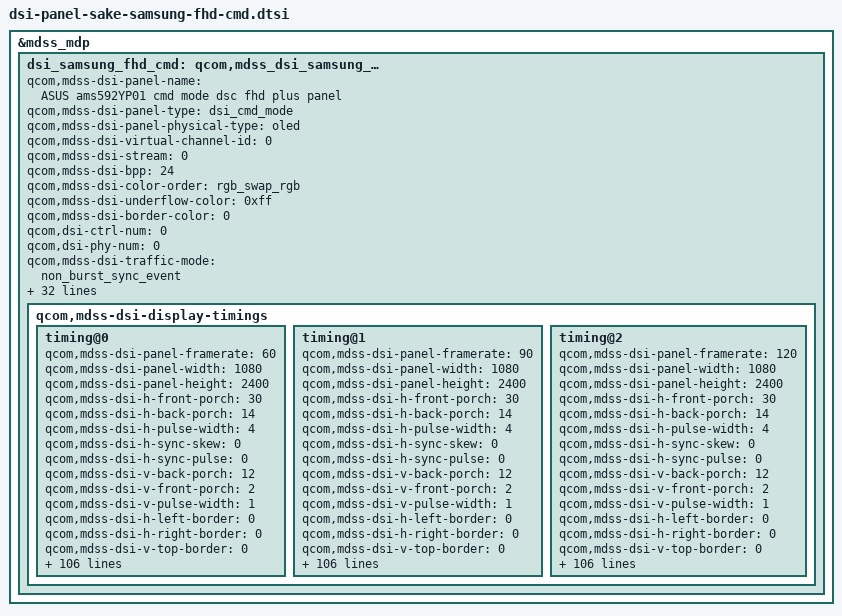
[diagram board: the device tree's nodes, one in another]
&mdss_mdp {
	dsi_samsung_fhd_cmd: qcom,mdss_dsi_samsung_fhd_cmd {
		qcom,mdss-dsi-panel-name = "ASUS ams592YP01 cmd mode dsc fhd plus panel";
		qcom,mdss-dsi-panel-type = "dsi_cmd_mode";
		qcom,mdss-dsi-panel-physical-type = "oled";
		qcom,mdss-dsi-virtual-channel-id = <0>;
		qcom,mdss-dsi-stream = <0>;
		qcom,mdss-dsi-bpp = <24>;
		qcom,mdss-dsi-color-order = "rgb_swap_rgb";
		qcom,mdss-dsi-underflow-color = <0xff>;
		qcom,mdss-dsi-border-color = <0>;

		qcom,dsi-ctrl-num = <0>;
		qcom,dsi-phy-num = <0>;

		qcom,mdss-dsi-traffic-mode = "non_burst_sync_event";
		qcom,mdss-dsi-lane-map = "lane_map_0123";
		qcom,mdss-dsi-bllp-eof-power-mode;
		qcom,mdss-dsi-bllp-power-mode;
		qcom,mdss-dsi-lane-0-state;
		qcom,mdss-dsi-lane-1-state;
		qcom,mdss-dsi-lane-2-state;
		qcom,mdss-dsi-lane-3-state;
		qcom,mdss-dsi-dma-trigger = "trigger_sw";
		qcom,mdss-dsi-mdp-trigger = "none";
		qcom,mdss-dsi-reset-sequence = <0 1>,<0 1>, <1 10>;
		qcom,mdss-dsi-te-pin-select = <1>;
		qcom,mdss-dsi-wr-mem-start = <0x2c>;
		qcom,mdss-dsi-wr-mem-continue = <0x3c>;
		qcom,mdss-dsi-te-dcs-command = <1>;
		qcom,mdss-dsi-te-check-enable;
		qcom,mdss-dsi-te-using-te-pin;
		qcom,mdss-pan-physical-width-dimension = <62>;
		qcom,mdss-pan-physical-height-dimension = <137>;
		qcom,mdss-dsi-panel-hdr-enabled;
		qcom,mdss-dsi-panel-hdr-color-primaries = <15635 16450 34000
			16000 13250 34500 7500 3000>;
		qcom,mdss-dsi-panel-peak-brightness = <4500000>;
		qcom,mdss-dsi-panel-blackness-level = <5>;

		qcom,mdss-dsi-panel-vendor-id = "AMS592YP01";
		qcom,mdss-dsi-bl-inverted-dbv;
		qcom,dynamic-mode-switch-enabled;
		qcom,dynamic-mode-switch-type = "dynamic-resolution-switch-immediate";
		qcom,ulps-enabled;
		qcom,mdss-dsi-lp11-init;

		qcom,fod-dim-lut = <
			/* brightness, alpha */
			0	0xf0
			4	0xea
			8	0xe8
			12	0xe4
			16	0xe0
			20	0xdd
			24	0xda
			28	0xd8
			32	0xd7
			36	0xd4
			40	0xd2
			44	0xd0
			48	0xce
			52	0xcd
			56	0xcc
			60	0xcb
			64	0xc9
			68	0xc8
			72	0xc7
			76	0xc5
			80	0xc3
			84	0xc2
			88	0xc0
			92	0xbf
			96	0xbe
			100	0xbd
			104	0xbc
			108	0xbb
			112	0xb9
			116	0xb8
			120	0xb7
			124	0xb6
			128	0xb5
			132	0xb4
			136	0xb2
			140	0xb1
			144	0xb1
			148	0xb0
			152	0xae
			156	0xae
			160	0xad
			164	0xac
			168	0xab
			172	0xab
			176	0xa9
			180	0xa9
			184	0xa8
			188	0xa4
			192	0xa4
			196	0xa3
			200	0xa3
			204	0xa3
			208	0xa3
			212	0xa3
			216	0xa3
			220	0xa2
			224	0xa2
			228	0xa1
			232	0xa1
			236	0xa0
			240	0xa0
			244	0xa0
			248	0x9f
			252	0x9e
			256	0x9d
			260	0x9c
			264	0x9c
			268	0x9b
			272	0x9a
			276	0x99
			280	0x98
			284	0x98
			288	0x96
			292	0x96
			296	0x95
			300	0x94
			304	0x94
			308	0x92
			312	0x92
			316	0x91
			320	0x91
			324	0x90
			328	0x90
			332	0x8f
			336	0x8d
			341	0x8d
			345	0x8c
			349	0x8c
			353	0x8b
			357	0x8b
			361	0x8a
			365	0x89
			369	0x89
			373	0x88
			377	0x88
			381	0x86
			385	0x86
			389	0x85
			393	0x85
			397	0x84
			401	0x84
			405	0x83
			409	0x83
			413	0x82
			417	0x81
			421	0x81
			425	0x80
			429	0x80
			433	0x7f
			437	0x7f
			441	0x7e
			445	0x7d
			449	0x7d
			453	0x7c
			457	0x7c
			461	0x7a
			465	0x7a
			469	0x79
			473	0x79
			477	0x78
			481	0x78
			485	0x78
			489	0x76
			493	0x76
			497	0x76
			501	0x75
			505	0x75
			509	0x74
			513	0x74
			517	0x73
			521	0x73
			525	0x73
			529	0x71
			533	0x70
			537	0x6f
			541	0x6f
			545	0x6f
			549	0x6d
			553	0x6d
			557	0x6d
			561	0x6c
			565	0x6c
			569	0x6b
			573	0x6a
			577	0x6a
			581	0x69
			585	0x69
			589	0x69
			593	0x68
			597	0x68
			601	0x68
			605	0x66
			609	0x66
			613	0x66
			617	0x65
			621	0x65
			625	0x65
			629	0x64
			633	0x64
			637	0x63
			641	0x63
			645	0x63
			649	0x63
			653	0x61
			657	0x61
			661	0x61
			665	0x60
			669	0x60
			673	0x60
			677	0x5f
			682	0x5f
			686	0x5e
			690	0x5d
			694	0x5c
			698	0x5c
			702	0x5c
			706	0x5b
			710	0x5a
			714	0x5a
			718	0x59
			722	0x59
			726	0x59
			730	0x58
			734	0x58
			738	0x58
			742	0x57
			746	0x57
			750	0x57
			754	0x56
			758	0x55
			762	0x55
			766	0x54
			770	0x54
			774	0x54
			778	0x53
			782	0x53
			786	0x53
			790	0x52
			794	0x51
			798	0x51
			802	0x51
			806	0x50
			810	0x50
			814	0x50
			818	0x4f
			822	0x4e
			826	0x4e
			830	0x4d
			834	0x4c
			838	0x4c
			842	0x4c
			846	0x4b
			850	0x4a
			854	0x4a
			858	0x49
			862	0x49
			866	0x49
			870	0x48
			874	0x48
			878	0x48
			882	0x47
			886	0x47
			890	0x47
			894	0x46
			898	0x45
			902	0x45
			906	0x45
			910	0x45
			914	0x44
			918	0x44
			922	0x44
			926	0x44
			930	0x44
			934	0x44
			938	0x43
			942	0x43
			946	0x43
			950	0x42
			954	0x41
			958	0x41
			962	0x41
			966	0x40
			970	0x40
			974	0x40
			978	0x3f
			982	0x3e
			986	0x3e
			990	0x3e
			994	0x3e
			998	0x3d
			1002	0x3d
			1006	0x3d
			1010	0x3c
			1014	0x3c
			1018	0x3c
			1023	0x3c
		>;

		qcom,mdss-dsi-display-timings {
			timing@0{
				qcom,mdss-dsi-panel-framerate = <60>;
				qcom,mdss-dsi-panel-width = <1080>;
				qcom,mdss-dsi-panel-height = <2400>;
				qcom,mdss-dsi-h-front-porch = <30>;
				qcom,mdss-dsi-h-back-porch = <14>;
				qcom,mdss-dsi-h-pulse-width = <4>;
				qcom,mdss-dsi-h-sync-skew = <0>;
				qcom,mdss-dsi-h-sync-pulse = <0>;
				qcom,mdss-dsi-v-back-porch = <12>;
				qcom,mdss-dsi-v-front-porch = <2>;
				qcom,mdss-dsi-v-pulse-width = <1>;
				qcom,mdss-dsi-h-left-border = <0>;
				qcom,mdss-dsi-h-right-border = <0>;
				qcom,mdss-dsi-v-top-border = <0>;
				qcom,mdss-dsi-v-bottom-border = <0>;
				qcom,mdss-dsi-panel-jitter = <0x05 0xa>;
				qcom,mdss-dsi-panel-clockrate = <1100000000>;

				qcom,mdss-dsi-on-command = [
					05 01 00 00 0A 00 02 11 00
 					//6 PPS Setting
					39 01 00 00 00 00 81 9E 11 00 00 89 30 80 09 60 04 38 00 28 02 1C 02 1C 02 00 02 0E 00 20 03 DD 00 07 00 0C 02 77 02 8B 18 00 10 F0 03 0C 20 00 06 0B 0B 33 0E 1C 2A 38 46 54 62 69 70 77 79 7B 7D 7E 01 02 01 00 09 40 09 BE 19 FC 19 FA 19 F8 1A 38 1A 78 1A B6 2A F6 2B 34 2B 74 3B 74 6B F4 00 00 00 00 00 00 00 00 00 00 00 00 00 00 00 00 00 00 00 00 00 00 00 00 00 00 00 00 00 00 00 00 00 00 00 00 00 00 00 00 
					15 01 00 00 00 00 02 C2 14
					15 01 00 00 00 00 02 9D 01
					//5.1 TE ON
 					15 01 00 00 0A 00 02 35 00
					//5.2 CASET/PASET Setting
					39 01 00 00 00 00 05 2A 00 00 04 37
					39 01 00 00 00 00 05 2B 00 00 09 5F
					//5.3 FQ_CON Setting
					39 01 00 00 00 00 03 F0 5A 5A
					39 01 00 00 00 00 03 B0 27 F2
					15 01 00 00 00 00 02 F2 00
					39 01 00 00 00 00 03 F0 A5 A5
					//5.4 Frequency Change  60-120Hz
					39 01 00 00 00 00 03 F0 5A 5A
					39 01 00 00 00 00 03 60 08 00
					15 01 00 00 00 00 02 F7 0F
					39 01 00 00 00 00 03 F0 A5 A5
					//7 Frequency Setting  90-120Hz
					39 01 00 00 00 00 03 F0 5A 5A
					39 01 00 00 00 00 03 B0 09 F2
					39 01 00 00 00 00 03 F2 26 F8
					39 01 00 00 00 00 03 F0 A5 A5
                                        //5.5 Porch clock Set
					39 01 00 00 00 00 03 F0 5A 5A
					39 01 00 00 00 00 03 B0 2E F2
					15 01 00 00 00 00 02 F2 55
					15 01 00 00 00 00 02 F7 0F
					39 01 00 00 00 00 03 F0 A5 A5
					//8.1 Dimming Setting
					39 01 00 00 00 00 03 F0 5A 5A
					39 01 00 00 00 00 03 B0 91 63
					15 01 00 00 00 00 02 63 14
					15 01 00 00 00 00 02 53 20
                                        39 01 00 00 00 00 03 51 00 00
					39 01 00 00 00 00 03 F0 A5 A5
					//8.3 HBM Off Setting
					15 01 00 00 00 00 02 53 28
					//8.4 ACL Mode Off
                                        15 01 00 00 00 00 02 55 00
					05 01 00 00 00 00 02 29 00
					//5.4 Frequency Change  120-60Hz
					39 01 00 00 00 00 03 F0 5A 5A
					39 01 00 00 00 00 03 60 00 00
					15 01 00 00 00 00 02 F7 0F
					39 01 00 00 00 00 03 F0 A5 A5
				];

				qcom,mdss-dsi-ER1-on-command = [
					05 01 00 00 78 00 02 11 00
 					//6 PPS Setting
					39 01 00 00 00 00 81 9E 11 00 00 89 30 80 09 60 04 38 00 28 02 1C 02 1C 02 00 02 0E 00 20 03 DD 00 07 00 0C 02 77 02 8B 18 00 10 F0 03 0C 20 00 06 0B 0B 33 0E 1C 2A 38 46 54 62 69 70 77 79 7B 7D 7E 01 02 01 00 09 40 09 BE 19 FC 19 FA 19 F8 1A 38 1A 78 1A B6 2A F6 2B 34 2B 74 3B 74 6B F4 00 00 00 00 00 00 00 00 00 00 00 00 00 00 00 00 00 00 00 00 00 00 00 00 00 00 00 00 00 00 00 00 00 00 00 00 00 00 00 00 
					15 01 00 00 00 00 02 C2 14
					15 01 00 00 00 00 02 9D 01
					//5.1 TE ON
 					15 01 00 00 0A 00 02 35 00
					//5.2 CASET/PASET Setting
					39 01 00 00 00 00 05 2A 00 00 04 37
					39 01 00 00 00 00 05 2B 00 00 09 5F
					//5.3 FQ_CON Setting
					39 01 00 00 00 00 03 F0 5A 5A
					39 01 00 00 00 00 03 B0 27 F2
					15 01 00 00 00 00 02 F2 00
					39 01 00 00 00 00 03 F0 A5 A5
					//5.4 Frequency Change  60-120Hz
					39 01 00 00 00 00 03 F0 5A 5A
					39 01 00 00 00 00 03 60 08 00
					15 01 00 00 00 00 02 F7 0F
					39 01 00 00 00 00 03 F0 A5 A5
					//7 Frequency Setting  90-120Hz
					39 01 00 00 00 00 03 F0 5A 5A
					39 01 00 00 00 00 03 B0 09 F2
					39 01 00 00 00 00 03 F2 26 F8
					39 01 00 00 00 00 03 F0 A5 A5
                                        //5.5 Porch clock Set
					39 01 00 00 00 00 03 F0 5A 5A
					39 01 00 00 00 00 03 B0 2E F2
					15 01 00 00 00 00 02 F2 55
					15 01 00 00 00 00 02 F7 0F
					39 01 00 00 00 00 03 F0 A5 A5
					//8.1 Dimming Setting
					39 01 00 00 00 00 03 F0 5A 5A
					39 01 00 00 00 00 03 B0 91 63
					15 01 00 00 00 00 02 63 14
					15 01 00 00 00 00 02 53 20
                                        39 01 00 00 00 00 03 51 00 00
					39 01 00 00 00 00 03 F0 A5 A5
					//8.3 HBM Off Setting
					15 01 00 00 00 00 02 53 28
					//8.4 ACL Mode Off
                                        15 01 00 00 00 00 02 55 00
					05 01 00 00 00 00 02 29 00
					//5.4 Frequency Change  120-60Hz
					39 01 00 00 00 00 03 F0 5A 5A
					39 01 00 00 00 00 03 60 00 00
					15 01 00 00 00 00 02 F7 0F
					39 01 00 00 00 00 03 F0 A5 A5
				];

				qcom,mdss-dsi-off-command = [
					05 01 00 00 0A 00 02 28 00
					05 01 00 00 78 00 02 10 00
				];

				qcom,mdss-dsi-timing-switch-command = [
					39 01 00 00 00 00 03 F0 5A 5A
					39 01 00 00 00 00 03 60 08 00
					15 01 00 00 00 00 02 F7 0F
					39 01 00 00 00 00 03 F0 A5 A5
					39 01 00 00 00 00 03 F0 5A 5A
					39 01 00 00 00 00 03 B0 09 F2
					39 01 00 00 00 00 03 F2 26 F8
					39 01 00 00 00 00 03 F0 A5 A5
					39 01 00 00 00 00 03 F0 5A 5A
					39 01 00 00 00 00 03 60 00 00
					15 01 00 00 00 00 02 F7 0F
					39 01 00 00 00 00 03 F0 A5 A5
				];

				qcom,mdss-dsi-hbm-on-command = [
					15 01 00 00 00 00 02 53 E8
					39 01 00 00 00 00 03 51 03 FF
				];
	
				qcom,mdss-dsi-hbm-ER2-on-command = [
					15 01 00 00 00 00 02 53 E8
					39 01 00 00 00 00 03 51 07 1C
				];

				qcom,mdss-dsi-ER1-cam-hbm-on-command = [
					15 01 00 00 00 00 02 53 E8
					39 01 00 00 00 00 03 51 02 F2
				];

				qcom,mdss-dsi-ER2-cam-hbm-on-command = [
					15 01 00 00 00 00 02 53 E8
					39 01 00 00 00 00 03 51 06 28
				];

				qcom,mdss-dsi-hbm-off-command = [
					15 01 00 00 00 00 02 53 28
					39 01 00 00 00 00 03 51 03 FF
				];

				qcom,mdss-dsi-fod-hbm-on-command = [
					// ELVSS DIM OFF & DLY OFF
					39 01 00 00 00 00 03 F0 5A 5A
					39 01 00 00 00 00 03 B0 91 63
					15 01 00 00 00 00 02 63 20
					39 01 00 00 00 00 03 F0 A5 A5
					// HBM ON
					15 01 00 00 00 00 02 53 E0
					39 01 00 00 00 00 03 51 03 FF
				];

				qcom,mdss-dsi-fod-ER2-hbm-on-command = [
					// ELVSS DIM OFF & DLY OFF
					39 01 00 00 00 00 03 F0 5A 5A
					39 01 00 00 00 00 03 B0 91 63
					15 01 00 00 00 00 02 63 20
					39 01 00 00 00 00 03 F0 A5 A5
					// HBM ON
					15 01 00 00 00 00 02 53 E0
					39 01 00 00 00 00 03 51 07 1C
				];

				qcom,mdss-dsi-fod-hbm-off-command = [
					// HBM OFF
					15 01 00 00 00 00 02 53 20
					// ELVSS DIM ON & DLY ON
					39 01 00 00 00 00 03 F0 5A 5A
					39 01 00 00 00 00 03 B0 91 63
					15 01 00 00 00 00 02 63 50
					39 01 00 00 00 00 03 F0 A5 A5
				];

				qcom,mdss-dsi-lp1-command = [
					//5.4 Frequency Change  60-120Hz
					39 01 00 00 00 00 03 F0 5A 5A
					39 01 00 00 00 00 03 60 08 00
					15 01 00 00 00 00 02 F7 0F
					39 01 00 00 00 00 03 F0 A5 A5
					05 01 00 00 10 00 02 28 00
				];

				qcom,mdss-dsi-nolp-command = [
					//4.2 AOD Mode OFF Setting
					15 01 00 00 00 00 02 53 20
					05 01 00 00 00 00 02 29 00
					//5.4 Frequency Change  120-60Hz
					39 01 00 00 00 00 03 F0 5A 5A
					39 01 00 00 00 00 03 60 00 00
					15 01 00 00 00 00 02 F7 0F
					39 01 00 00 00 00 03 F0 A5 A5
				];

				qcom,mdss-dsi-nolp-ER2-command = [
					//4.2 AOD Mode OFF Setting
					39 01 00 00 00 00 03 F0 5A 5A
					15 01 00 00 00 00 02 53 20
					15 01 00 00 00 00 02 91 02
					39 01 00 00 00 00 03 F0 A5 A5
					05 01 00 00 00 00 02 29 00
					//5.4 Frequency Change  120-60Hz
					39 01 00 00 00 00 03 F0 5A 5A
					39 01 00 00 00 00 03 60 00 00
					15 01 00 00 00 00 02 F7 0F
					39 01 00 00 00 00 03 F0 A5 A5
				];

				qcom,mdss-dsi-nolp-ER2-FOD-command = [
					//4.2 AOD Mode OFF Setting
					39 01 00 00 00 00 03 F0 5A 5A
					15 01 00 00 00 00 02 53 20
					15 01 00 00 00 00 02 91 02
					39 01 00 00 00 00 03 F0 A5 A5
					15 01 00 00 00 00 02 53 E0
					39 01 00 00 00 00 03 51 07 1C
					05 01 00 00 00 00 02 29 00
					//5.4 Frequency Change  120-60Hz
					39 01 00 00 00 00 03 F0 5A 5A
					39 01 00 00 00 00 03 60 00 00
					15 01 00 00 00 00 02 F7 0F
					39 01 00 00 00 00 03 F0 A5 A5
				];

				qcom,mdss-dsi-aod-high-command = [
					// 24 for 40 nit
					15 01 00 00 10 00 02 53 24
					05 01 00 00 00 00 02 29 00
				];

				qcom,mdss-dsi-aod-low-command = [
					// 25 for 40 nit
					15 01 00 00 10 00 02 53 25
					05 01 00 00 00 00 02 29 00
				];

				qcom,mdss-dsi-aod-ER2-high-command = [
					// 24 for 40 nit
					39 01 00 00 00 00 03 F0 5A 5A
					15 01 00 00 00 00 02 91 01
					15 01 00 00 10 00 02 53 24
					39 01 00 00 00 00 03 F0 A5 A5
					05 01 00 00 00 00 02 29 00
				];

				qcom,mdss-dsi-aod-ER2-low-command = [
					// 25 for Low Mode
					39 01 00 00 00 00 03 F0 5A 5A
					15 01 00 00 00 00 02 91 01
					15 01 00 00 10 00 02 53 25
					39 01 00 00 00 00 03 F0 A5 A5
					05 01 00 00 00 00 02 29 00
				];

				qcom,mdss-dsi-aod-other-command = [
					05 01 00 00 00 00 02 29 00
				];

				qcom,mdss-dsi-dimming-speed-1frame-command = [
					15 01 00 00 00 00 02 53 20
				];

				qcom,mdss-dsi-dimming-speed-20frame-command = [
					15 01 00 00 00 00 02 53 28
				];

				qcom,mdss-dsi-dimming-smooth-command = [
					15 01 00 00 00 00 02 53 28
				];

				qcom,mdss-dsi-aod-off-command = [
					05 01 00 00 10 00 02 28 00
				];

				qcom,mdss-dsi-on-command-state = "dsi_lp_mode";
				qcom,mdss-dsi-ER1-on-command-state = "dsi_lp_mode";
				qcom,mdss-dsi-off-command-state = "dsi_hs_mode";
				qcom,mdss-dsi-timing-switch-command-state = "dsi_hs_mode";
				qcom,mdss-dsi-hbm-on-command-state = "dsi_hs_mode";
				qcom,mdss-dsi-hbm-ER2-on-command-state = "dsi_hs_mode";
				qcom,mdss-dsi-ER1-cam-hbm-on-command-state = "dsi_hs_mode";
				qcom,mdss-dsi-ER2-cam-hbm-on-command-state = "dsi_hs_mode";
				qcom,mdss-dsi-hbm-off-command-state = "dsi_hs_mode";
				qcom,mdss-dsi-fod-hbm-on-command-state = "dsi_hs_mode";
				qcom,mdss-dsi-fod-ER2-hbm-on-command-state = "dsi_hs_mode";
				qcom,mdss-dsi-fod-hbm-off-command-state = "dsi_hs_mode";
				qcom,mdss-dsi-lp1-command-state = "dsi_hs_mode";
				qcom,mdss-dsi-nolp-command-state = "dsi_hs_mode";
				qcom,mdss-dsi-nolp-ER2-command-state = "dsi_hs_mode";
				qcom,mdss-dsi-nolp-ER2-FOD-command-state = "dsi_hs_mode";
				qcom,mdss-dsi-aod-high-command-state = "dsi_hs_mode";
				qcom,mdss-dsi-aod-low-command-state = "dsi_hs_mode";
				qcom,mdss-dsi-aod-ER2-high-command-state = "dsi_hs_mode";
				qcom,mdss-dsi-aod-ER2-low-command-state = "dsi_hs_mode";
				qcom,mdss-dsi-aod-other-command-state = "dsi_hs_mode";
				qcom,mdss-dsi-dimming-speed-1frame-command-state = "dsi_hs_mode";
				qcom,mdss-dsi-dimming-speed-20frame-command-state = "dsi_hs_mode";
				qcom,mdss-dsi-dimming-smooth-command-state = "dsi_hs_mode";
				qcom,mdss-dsi-aod-off-command-state = "dsi_hs_mode";


				/* DSC */
				qcom,compression-mode = "dsc";
				qcom,mdss-dsc-slice-height = <40>;
				qcom,mdss-dsc-slice-width = <540>;
				qcom,mdss-dsc-slice-per-pkt = <1>;
				qcom,mdss-dsc-bit-per-component = <8>;
				qcom,mdss-dsc-bit-per-pixel = <8>;
				qcom,mdss-dsc-block-prediction-enable;
			};

			timing@1{
				qcom,mdss-dsi-panel-framerate = <90>;
				qcom,mdss-dsi-panel-width = <1080>;
				qcom,mdss-dsi-panel-height = <2400>;
				qcom,mdss-dsi-h-front-porch = <30>;
				qcom,mdss-dsi-h-back-porch = <14>;
				qcom,mdss-dsi-h-pulse-width = <4>;
				qcom,mdss-dsi-h-sync-skew = <0>;
				qcom,mdss-dsi-h-sync-pulse = <0>;
				qcom,mdss-dsi-v-back-porch = <12>;
				qcom,mdss-dsi-v-front-porch = <2>;
				qcom,mdss-dsi-v-pulse-width = <1>;
				qcom,mdss-dsi-h-left-border = <0>;
				qcom,mdss-dsi-h-right-border = <0>;
				qcom,mdss-dsi-v-top-border = <0>;
				qcom,mdss-dsi-v-bottom-border = <0>;
				qcom,mdss-dsi-panel-jitter = <0x05 0xa>;
				qcom,mdss-dsi-panel-clockrate = <1100000000>;

				qcom,mdss-dsi-on-command = [
					05 01 00 00 0A 00 02 11 00
 					//6 PPS Setting
					39 01 00 00 00 00 81 9E 11 00 00 89 30 80 09 60 04 38 00 28 02 1C 02 1C 02 00 02 0E 00 20 03 DD 00 07 00 0C 02 77 02 8B 18 00 10 F0 03 0C 20 00 06 0B 0B 33 0E 1C 2A 38 46 54 62 69 70 77 79 7B 7D 7E 01 02 01 00 09 40 09 BE 19 FC 19 FA 19 F8 1A 38 1A 78 1A B6 2A F6 2B 34 2B 74 3B 74 6B F4 00 00 00 00 00 00 00 00 00 00 00 00 00 00 00 00 00 00 00 00 00 00 00 00 00 00 00 00 00 00 00 00 00 00 00 00 00 00 00 00 
					15 01 00 00 00 00 02 C2 14
					15 01 00 00 00 00 02 9D 01
					//5.1 TE ON
 					15 01 00 00 0A 00 02 35 00
					//5.2 CASET/PASET Setting
					39 01 00 00 00 00 05 2A 00 00 04 37
					39 01 00 00 00 00 05 2B 00 00 09 5F
					//5.3 FQ_CON Setting
					39 01 00 00 00 00 03 F0 5A 5A
					39 01 00 00 00 00 03 B0 27 F2
					15 01 00 00 00 00 02 F2 00
					39 01 00 00 00 00 03 F0 A5 A5
					//5.4 Frequency Change  60-120Hz
					39 01 00 00 00 00 03 F0 5A 5A
					39 01 00 00 00 00 03 60 08 00
					15 01 00 00 00 00 02 F7 0F
					39 01 00 00 00 00 03 F0 A5 A5
					//7 Frequency Setting  90-120Hz
					39 01 00 00 00 00 03 F0 5A 5A
					39 01 00 00 00 00 03 B0 09 F2
					39 01 00 00 00 00 03 F2 26 F8
					39 01 00 00 00 00 03 F0 A5 A5
                                        //5.5 Porch clock Set
					39 01 00 00 00 00 03 F0 5A 5A
					39 01 00 00 00 00 03 B0 2E F2
					15 01 00 00 00 00 02 F2 55
					15 01 00 00 00 00 02 F7 0F
					39 01 00 00 00 00 03 F0 A5 A5
					//8.1 Dimming Setting
					39 01 00 00 00 00 03 F0 5A 5A
					39 01 00 00 00 00 03 B0 91 63
					15 01 00 00 00 00 02 63 14
					15 01 00 00 00 00 02 53 20
                                        39 01 00 00 00 00 03 51 00 00
					39 01 00 00 00 00 03 F0 A5 A5
					//8.3 HBM Off Setting
					15 01 00 00 00 00 02 53 28
					//8.4 ACL Mode Off
                                        15 01 00 00 00 00 02 55 00
					05 01 00 00 00 00 02 29 00
					//5.4 Frequency Change  120-90Hz
					39 01 00 00 00 00 03 F0 5A 5A
					39 01 00 00 00 00 03 B0 09 F2
					39 01 00 00 00 00 03 F2 33 A8
					39 01 00 00 00 00 03 F0 A5 A5
				];

				qcom,mdss-dsi-ER1-on-command = [
					05 01 00 00 78 00 02 11 00
 					//6 PPS Setting
					39 01 00 00 00 00 81 9E 11 00 00 89 30 80 09 60 04 38 00 28 02 1C 02 1C 02 00 02 0E 00 20 03 DD 00 07 00 0C 02 77 02 8B 18 00 10 F0 03 0C 20 00 06 0B 0B 33 0E 1C 2A 38 46 54 62 69 70 77 79 7B 7D 7E 01 02 01 00 09 40 09 BE 19 FC 19 FA 19 F8 1A 38 1A 78 1A B6 2A F6 2B 34 2B 74 3B 74 6B F4 00 00 00 00 00 00 00 00 00 00 00 00 00 00 00 00 00 00 00 00 00 00 00 00 00 00 00 00 00 00 00 00 00 00 00 00 00 00 00 00 
					15 01 00 00 00 00 02 C2 14
					15 01 00 00 00 00 02 9D 01
					//5.1 TE ON
 					15 01 00 00 0A 00 02 35 00
					//5.2 CASET/PASET Setting
					39 01 00 00 00 00 05 2A 00 00 04 37
					39 01 00 00 00 00 05 2B 00 00 09 5F
					//5.3 FQ_CON Setting
					39 01 00 00 00 00 03 F0 5A 5A
					39 01 00 00 00 00 03 B0 27 F2
					15 01 00 00 00 00 02 F2 00
					39 01 00 00 00 00 03 F0 A5 A5
					//5.4 Frequency Change  60-120Hz
					39 01 00 00 00 00 03 F0 5A 5A
					39 01 00 00 00 00 03 60 08 00
					15 01 00 00 00 00 02 F7 0F
					39 01 00 00 00 00 03 F0 A5 A5
					//7 Frequency Setting  90-120Hz
					39 01 00 00 00 00 03 F0 5A 5A
					39 01 00 00 00 00 03 B0 09 F2
					39 01 00 00 00 00 03 F2 26 F8
					39 01 00 00 00 00 03 F0 A5 A5
                                        //5.5 Porch clock Set
					39 01 00 00 00 00 03 F0 5A 5A
					39 01 00 00 00 00 03 B0 2E F2
					15 01 00 00 00 00 02 F2 55
					15 01 00 00 00 00 02 F7 0F
					39 01 00 00 00 00 03 F0 A5 A5
					//8.1 Dimming Setting
					39 01 00 00 00 00 03 F0 5A 5A
					39 01 00 00 00 00 03 B0 91 63
					15 01 00 00 00 00 02 63 14
					15 01 00 00 00 00 02 53 20
                                        39 01 00 00 00 00 03 51 00 00
					39 01 00 00 00 00 03 F0 A5 A5
					//8.3 HBM Off Setting
					15 01 00 00 00 00 02 53 28
					//8.4 ACL Mode Off
                                        15 01 00 00 00 00 02 55 00
					05 01 00 00 00 00 02 29 00
					//5.4 Frequency Change  120-90Hz
					39 01 00 00 00 00 03 F0 5A 5A
					39 01 00 00 00 00 03 B0 09 F2
					39 01 00 00 00 00 03 F2 33 A8
					39 01 00 00 00 00 03 F0 A5 A5
				];

				qcom,mdss-dsi-off-command = [
					05 01 00 00 0A 00 02 28 00
					05 01 00 00 78 00 02 10 00
				];

				qcom,mdss-dsi-timing-switch-command = [
					39 01 00 00 00 00 03 F0 5A 5A
					39 01 00 00 00 00 03 60 08 00
					15 01 00 00 00 00 02 F7 0F
					39 01 00 00 00 00 03 F0 A5 A5
					39 01 00 00 00 00 03 F0 5A 5A
					39 01 00 00 00 00 03 B0 09 F2
					39 01 00 00 00 00 03 F2 33 A8
					39 01 00 00 00 00 03 F0 A5 A5
				];

				qcom,mdss-dsi-hbm-on-command = [
					15 01 00 00 00 00 02 53 E8
					39 01 00 00 00 00 03 51 03 FF
				];
	
				qcom,mdss-dsi-hbm-ER2-on-command = [
					15 01 00 00 00 00 02 53 E8
					39 01 00 00 00 00 03 51 07 1C
				];

				qcom,mdss-dsi-ER1-cam-hbm-on-command = [
					15 01 00 00 00 00 02 53 E8
					39 01 00 00 00 00 03 51 02 F2
				];

				qcom,mdss-dsi-ER2-cam-hbm-on-command = [
					15 01 00 00 00 00 02 53 E8
					39 01 00 00 00 00 03 51 06 28
				];

				qcom,mdss-dsi-hbm-off-command = [
					15 01 00 00 00 00 02 53 28
					39 01 00 00 00 00 03 51 03 FF
				];

				qcom,mdss-dsi-fod-hbm-on-command = [
					// ELVSS DIM OFF & DLY OFF
					39 01 00 00 00 00 03 F0 5A 5A
					39 01 00 00 00 00 03 B0 91 63
					15 01 00 00 00 00 02 63 20
					39 01 00 00 00 00 03 F0 A5 A5
					// HBM ON
					15 01 00 00 00 00 02 53 E0
					39 01 00 00 00 00 03 51 03 FF
				];

				qcom,mdss-dsi-fod-ER2-hbm-on-command = [
					// ELVSS DIM OFF & DLY OFF
					39 01 00 00 00 00 03 F0 5A 5A
					39 01 00 00 00 00 03 B0 91 63
					15 01 00 00 00 00 02 63 20
					39 01 00 00 00 00 03 F0 A5 A5
					// HBM ON
					15 01 00 00 00 00 02 53 E0
					39 01 00 00 00 00 03 51 07 1C
				];

				qcom,mdss-dsi-fod-hbm-off-command = [
					// HBM OFF
					15 01 00 00 00 00 02 53 20
					// ELVSS DIM ON & DLY ON
					39 01 00 00 00 00 03 F0 5A 5A
					39 01 00 00 00 00 03 B0 91 63
					15 01 00 00 00 00 02 63 50
					39 01 00 00 00 00 03 F0 A5 A5
				];

				qcom,mdss-dsi-lp1-command = [
					//7 Frequency Setting  90-120Hz
					39 01 00 00 00 00 03 F0 5A 5A
					39 01 00 00 00 00 03 B0 09 F2
					39 01 00 00 00 00 03 F2 26 F8
					39 01 00 00 00 00 03 F0 A5 A5
					05 01 00 00 10 00 02 28 00
				];

				qcom,mdss-dsi-nolp-command = [
					//4.2 AOD Mode OFF Setting
					15 01 00 00 00 00 02 53 20
					05 01 00 00 00 00 02 29 00
					//5.4 Frequency Change  120-90Hz
					39 01 00 00 00 00 03 F0 5A 5A
					39 01 00 00 00 00 03 B0 09 F2
					39 01 00 00 00 00 03 F2 33 A8
					39 01 00 00 00 00 03 F0 A5 A5
				];

				qcom,mdss-dsi-nolp-ER2-command = [
					//4.2 AOD Mode OFF Setting
					39 01 00 00 00 00 03 F0 5A 5A
					15 01 00 00 00 00 02 53 20
					15 01 00 00 00 00 02 91 02
					39 01 00 00 00 00 03 F0 A5 A5
					05 01 00 00 00 00 02 29 00
					//5.4 Frequency Change  120-90Hz
					39 01 00 00 00 00 03 F0 5A 5A
					39 01 00 00 00 00 03 B0 09 F2
					39 01 00 00 00 00 03 F2 33 A8
					39 01 00 00 00 00 03 F0 A5 A5
				];

				qcom,mdss-dsi-nolp-ER2-FOD-command = [
					//4.2 AOD Mode OFF Setting
					39 01 00 00 00 00 03 F0 5A 5A
					15 01 00 00 00 00 02 53 20
					15 01 00 00 00 00 02 91 02
					39 01 00 00 00 00 03 F0 A5 A5
					15 01 00 00 00 00 02 53 E0
					39 01 00 00 00 00 03 51 07 1C
					05 01 00 00 00 00 02 29 00
					//5.4 Frequency Change  120-90Hz
					39 01 00 00 00 00 03 F0 5A 5A
					39 01 00 00 00 00 03 B0 09 F2
					39 01 00 00 00 00 03 F2 33 A8
					39 01 00 00 00 00 03 F0 A5 A5
				];

				qcom,mdss-dsi-aod-high-command = [
					// 24 for 40 nit
					15 01 00 00 10 00 02 53 24
					05 01 00 00 00 00 02 29 00
				];

				qcom,mdss-dsi-aod-low-command = [
					// 25 for 40 nit
					15 01 00 00 10 00 02 53 25
					05 01 00 00 00 00 02 29 00
				];

				qcom,mdss-dsi-aod-ER2-high-command = [
					// 24 for 40 nit
					39 01 00 00 00 00 03 F0 5A 5A
					15 01 00 00 00 00 02 91 01
					15 01 00 00 10 00 02 53 24
					39 01 00 00 00 00 03 F0 A5 A5
					05 01 00 00 00 00 02 29 00
				];

				qcom,mdss-dsi-aod-ER2-low-command = [
					// 25 for Low Mode
					39 01 00 00 00 00 03 F0 5A 5A
					15 01 00 00 00 00 02 91 01
					15 01 00 00 10 00 02 53 25
					39 01 00 00 00 00 03 F0 A5 A5
					05 01 00 00 00 00 02 29 00
				];

				qcom,mdss-dsi-aod-other-command = [
					05 01 00 00 00 00 02 29 00
				];

				qcom,mdss-dsi-dimming-speed-1frame-command = [
					15 01 00 00 00 00 02 53 20
				];

				qcom,mdss-dsi-dimming-speed-20frame-command = [
					15 01 00 00 00 00 02 53 28
				];

				qcom,mdss-dsi-dimming-smooth-command = [
					15 01 00 00 00 00 02 53 28
				];

				qcom,mdss-dsi-aod-off-command = [
					05 01 00 00 10 00 02 28 00
				];

				qcom,mdss-dsi-on-command-state = "dsi_lp_mode";
				qcom,mdss-dsi-ER1-on-command-state = "dsi_lp_mode";
				qcom,mdss-dsi-off-command-state = "dsi_hs_mode";
				qcom,mdss-dsi-timing-switch-command-state = "dsi_hs_mode";
				qcom,mdss-dsi-hbm-on-command-state = "dsi_hs_mode";
				qcom,mdss-dsi-hbm-ER2-on-command-state = "dsi_hs_mode";
				qcom,mdss-dsi-ER1-cam-hbm-on-command-state = "dsi_hs_mode";
				qcom,mdss-dsi-ER2-cam-hbm-on-command-state = "dsi_hs_mode";
				qcom,mdss-dsi-hbm-off-command-state = "dsi_hs_mode";
				qcom,mdss-dsi-fod-hbm-on-command-state = "dsi_hs_mode";
				qcom,mdss-dsi-fod-ER2-hbm-on-command-state = "dsi_hs_mode";
				qcom,mdss-dsi-fod-hbm-off-command-state = "dsi_hs_mode";
				qcom,mdss-dsi-lp1-command-state = "dsi_hs_mode";
				qcom,mdss-dsi-nolp-command-state = "dsi_hs_mode";
				qcom,mdss-dsi-nolp-ER2-command-state = "dsi_hs_mode";
				qcom,mdss-dsi-nolp-ER2-FOD-command-state = "dsi_hs_mode";
				qcom,mdss-dsi-aod-high-command-state = "dsi_hs_mode";
				qcom,mdss-dsi-aod-low-command-state = "dsi_hs_mode";
				qcom,mdss-dsi-aod-ER2-high-command-state = "dsi_hs_mode";
				qcom,mdss-dsi-aod-ER2-low-command-state = "dsi_hs_mode";
				qcom,mdss-dsi-aod-other-command-state = "dsi_hs_mode";
				qcom,mdss-dsi-dimming-speed-1frame-command-state = "dsi_hs_mode";
				qcom,mdss-dsi-dimming-speed-20frame-command-state = "dsi_hs_mode";
				qcom,mdss-dsi-dimming-smooth-command-state = "dsi_hs_mode";
				qcom,mdss-dsi-aod-off-command-state = "dsi_hs_mode";

				/* DSC */
				qcom,compression-mode = "dsc";
				qcom,mdss-dsc-slice-height = <40>;
				qcom,mdss-dsc-slice-width = <540>;
				qcom,mdss-dsc-slice-per-pkt = <1>;
				qcom,mdss-dsc-bit-per-component = <8>;
				qcom,mdss-dsc-bit-per-pixel = <8>;
				qcom,mdss-dsc-block-prediction-enable;
			};

			timing@2{
				qcom,mdss-dsi-panel-framerate = <120>;
				qcom,mdss-dsi-panel-width = <1080>;
				qcom,mdss-dsi-panel-height = <2400>;
				qcom,mdss-dsi-h-front-porch = <30>;
				qcom,mdss-dsi-h-back-porch = <14>;
				qcom,mdss-dsi-h-pulse-width = <4>;
				qcom,mdss-dsi-h-sync-skew = <0>;
				qcom,mdss-dsi-h-sync-pulse = <0>;
				qcom,mdss-dsi-v-back-porch = <12>;
				qcom,mdss-dsi-v-front-porch = <2>;
				qcom,mdss-dsi-v-pulse-width = <1>;
				qcom,mdss-dsi-h-left-border = <0>;
				qcom,mdss-dsi-h-right-border = <0>;
				qcom,mdss-dsi-v-top-border = <0>;
				qcom,mdss-dsi-v-bottom-border = <0>;
				qcom,mdss-dsi-panel-jitter = <0x05 0xa>;
				qcom,mdss-dsi-panel-clockrate = <1100000000>;

				qcom,mdss-dsi-on-command = [
					05 01 00 00 0A 00 02 11 00
 					//6 PPS Setting
					39 01 00 00 00 00 81 9E 11 00 00 89 30 80 09 60 04 38 00 28 02 1C 02 1C 02 00 02 0E 00 20 03 DD 00 07 00 0C 02 77 02 8B 18 00 10 F0 03 0C 20 00 06 0B 0B 33 0E 1C 2A 38 46 54 62 69 70 77 79 7B 7D 7E 01 02 01 00 09 40 09 BE 19 FC 19 FA 19 F8 1A 38 1A 78 1A B6 2A F6 2B 34 2B 74 3B 74 6B F4 00 00 00 00 00 00 00 00 00 00 00 00 00 00 00 00 00 00 00 00 00 00 00 00 00 00 00 00 00 00 00 00 00 00 00 00 00 00 00 00 
					15 01 00 00 00 00 02 C2 14
					15 01 00 00 00 00 02 9D 01
					//5.1 TE ON
 					15 01 00 00 0A 00 02 35 00
					//5.2 CASET/PASET Setting
					39 01 00 00 00 00 05 2A 00 00 04 37
					39 01 00 00 00 00 05 2B 00 00 09 5F
					//5.3 FQ_CON Setting
					39 01 00 00 00 00 03 F0 5A 5A
					39 01 00 00 00 00 03 B0 27 F2
					15 01 00 00 00 00 02 F2 00
					39 01 00 00 00 00 03 F0 A5 A5
					//5.4 Frequency Change  60-120Hz
					39 01 00 00 00 00 03 F0 5A 5A
					39 01 00 00 00 00 03 60 08 00
					15 01 00 00 00 00 02 F7 0F
					39 01 00 00 00 00 03 F0 A5 A5
					//7 Frequency Setting  90-120Hz
					39 01 00 00 00 00 03 F0 5A 5A
					39 01 00 00 00 00 03 B0 09 F2
					39 01 00 00 00 00 03 F2 26 F8
					39 01 00 00 00 00 03 F0 A5 A5
                                        //5.5 Porch clock Set
					39 01 00 00 00 00 03 F0 5A 5A
					39 01 00 00 00 00 03 B0 2E F2
					15 01 00 00 00 00 02 F2 55
					15 01 00 00 00 00 02 F7 0F
					39 01 00 00 00 00 03 F0 A5 A5
					//8.1 Dimming Setting
					39 01 00 00 00 00 03 F0 5A 5A
					39 01 00 00 00 00 03 B0 91 63
					15 01 00 00 00 00 02 63 14
					15 01 00 00 00 00 02 53 20
                                        39 01 00 00 00 00 03 51 00 00
					39 01 00 00 00 00 03 F0 A5 A5
					//8.3 HBM Off Setting
					15 01 00 00 00 00 02 53 28
					//8.4 ACL Mode Off
                                        15 01 00 00 00 00 02 55 00
					05 01 00 00 00 00 02 29 00
				];

				qcom,mdss-dsi-ER1-on-command = [
					05 01 00 00 0A 00 02 11 00
 					//6 PPS Setting
					39 01 00 00 00 00 81 9E 11 00 00 89 30 80 09 60 04 38 00 28 02 1C 02 1C 02 00 02 0E 00 20 03 DD 00 07 00 0C 02 77 02 8B 18 00 10 F0 03 0C 20 00 06 0B 0B 33 0E 1C 2A 38 46 54 62 69 70 77 79 7B 7D 7E 01 02 01 00 09 40 09 BE 19 FC 19 FA 19 F8 1A 38 1A 78 1A B6 2A F6 2B 34 2B 74 3B 74 6B F4 00 00 00 00 00 00 00 00 00 00 00 00 00 00 00 00 00 00 00 00 00 00 00 00 00 00 00 00 00 00 00 00 00 00 00 00 00 00 00 00 
					15 01 00 00 00 00 02 C2 14
					15 01 00 00 00 00 02 9D 01
					//5.1 TE ON
 					15 01 00 00 0A 00 02 35 00
					//5.2 CASET/PASET Setting
					39 01 00 00 00 00 05 2A 00 00 04 37
					39 01 00 00 00 00 05 2B 00 00 09 5F
					//5.3 FQ_CON Setting
					39 01 00 00 00 00 03 F0 5A 5A
					39 01 00 00 00 00 03 B0 27 F2
					15 01 00 00 00 00 02 F2 00
					39 01 00 00 00 00 03 F0 A5 A5
					//5.4 Frequency Change  60-120Hz
					39 01 00 00 00 00 03 F0 5A 5A
					39 01 00 00 00 00 03 60 08 00
					15 01 00 00 00 00 02 F7 0F
					39 01 00 00 00 00 03 F0 A5 A5
					//7 Frequency Setting  90-120Hz
					39 01 00 00 00 00 03 F0 5A 5A
					39 01 00 00 00 00 03 B0 09 F2
					39 01 00 00 00 00 03 F2 26 F8
					39 01 00 00 00 00 03 F0 A5 A5
                                        //5.5 Porch clock Set
					39 01 00 00 00 00 03 F0 5A 5A
					39 01 00 00 00 00 03 B0 2E F2
					15 01 00 00 00 00 02 F2 55
					15 01 00 00 00 00 02 F7 0F
					39 01 00 00 00 00 03 F0 A5 A5
					//8.1 Dimming Setting
					39 01 00 00 00 00 03 F0 5A 5A
					39 01 00 00 00 00 03 B0 91 63
					15 01 00 00 00 00 02 63 14
					15 01 00 00 00 00 02 53 20
                                        39 01 00 00 00 00 03 51 00 00
					39 01 00 00 00 00 03 F0 A5 A5
					//8.3 HBM Off Setting
					15 01 00 00 00 00 02 53 28
					//8.4 ACL Mode Off
                                        15 01 00 00 00 00 02 55 00
					05 01 00 00 00 00 02 29 00
				];

				qcom,mdss-dsi-off-command = [
					05 01 00 00 0A 00 02 28 00
					05 01 00 00 78 00 02 10 00
				];

				qcom,mdss-dsi-timing-switch-command = [
					39 01 00 00 00 00 03 F0 5A 5A
					39 01 00 00 00 00 03 60 08 00
					15 01 00 00 00 00 02 F7 0F
					39 01 00 00 00 00 03 F0 A5 A5
					39 01 00 00 00 00 03 F0 5A 5A
					39 01 00 00 00 00 03 B0 09 F2
					39 01 00 00 00 00 03 F2 26 F8
					39 01 00 00 00 00 03 F0 A5 A5
					39 01 00 00 00 00 03 F0 5A 5A
					39 01 00 00 00 00 03 60 08 00
					15 01 00 00 00 00 02 F7 0F
					39 01 00 00 00 00 03 F0 A5 A5
				];

				qcom,mdss-dsi-hbm-on-command = [
					15 01 00 00 00 00 02 53 E8
					39 01 00 00 00 00 03 51 03 FF
				];
	
				qcom,mdss-dsi-hbm-ER2-on-command = [
					15 01 00 00 00 00 02 53 E8
					39 01 00 00 00 00 03 51 07 1C
				];

				qcom,mdss-dsi-ER1-cam-hbm-on-command = [
					15 01 00 00 00 00 02 53 E8
					39 01 00 00 00 00 03 51 02 F2
				];

				qcom,mdss-dsi-ER2-cam-hbm-on-command = [
					15 01 00 00 00 00 02 53 E8
					39 01 00 00 00 00 03 51 06 28
				];

				qcom,mdss-dsi-hbm-off-command = [
					15 01 00 00 00 00 02 53 28
					39 01 00 00 00 00 03 51 03 FF
				];

				qcom,mdss-dsi-fod-hbm-on-command = [
					// ELVSS DIM OFF & DLY OFF
					39 01 00 00 00 00 03 F0 5A 5A
					39 01 00 00 00 00 03 B0 91 63
					15 01 00 00 00 00 02 63 20
					39 01 00 00 00 00 03 F0 A5 A5
					// HBM ON
					15 01 00 00 00 00 02 53 E0
					39 01 00 00 00 00 03 51 03 FF
				];

				qcom,mdss-dsi-fod-ER2-hbm-on-command = [
					// ELVSS DIM OFF & DLY OFF
					39 01 00 00 00 00 03 F0 5A 5A
					39 01 00 00 00 00 03 B0 91 63
					15 01 00 00 00 00 02 63 20
					39 01 00 00 00 00 03 F0 A5 A5
					// HBM ON
					15 01 00 00 00 00 02 53 E0
					39 01 00 00 00 00 03 51 07 1C
				];

				qcom,mdss-dsi-fod-hbm-off-command = [
					// HBM OFF
					15 01 00 00 00 00 02 53 20
					// ELVSS DIM ON & DLY ON
					39 01 00 00 00 00 03 F0 5A 5A
					39 01 00 00 00 00 03 B0 91 63
					15 01 00 00 00 00 02 63 50
					39 01 00 00 00 00 03 F0 A5 A5
				];

				qcom,mdss-dsi-lp1-command = [
					05 01 00 00 10 00 02 28 00
				];

				qcom,mdss-dsi-nolp-command = [
					//4.2 AOD Mode OFF Setting
					15 01 00 00 00 00 02 53 20
					05 01 00 00 00 00 02 29 00
				];

				qcom,mdss-dsi-nolp-ER2-command = [
					//4.2 AOD Mode OFF Setting
					39 01 00 00 00 00 03 F0 5A 5A
					15 01 00 00 00 00 02 53 20
					15 01 00 00 00 00 02 91 02
					39 01 00 00 00 00 03 F0 A5 A5
					05 01 00 00 00 00 02 29 00
				];

				qcom,mdss-dsi-nolp-ER2-FOD-command = [
					//4.2 AOD Mode OFF Setting
					39 01 00 00 00 00 03 F0 5A 5A
					15 01 00 00 00 00 02 53 20
					15 01 00 00 00 00 02 91 02
					39 01 00 00 00 00 03 F0 A5 A5
					15 01 00 00 00 00 02 53 E0
					39 01 00 00 00 00 03 51 07 1C
					05 01 00 00 00 00 02 29 00
				];

				qcom,mdss-dsi-aod-high-command = [
					// 24 for 40 nit
					15 01 00 00 10 00 02 53 24
					05 01 00 00 00 00 02 29 00
				];

				qcom,mdss-dsi-aod-low-command = [
					// 25 for 40 nit
					15 01 00 00 10 00 02 53 25
					05 01 00 00 00 00 02 29 00
				];

				qcom,mdss-dsi-aod-ER2-high-command = [
					// 24 for 40 nit
					39 01 00 00 00 00 03 F0 5A 5A
					15 01 00 00 00 00 02 91 01
					15 01 00 00 10 00 02 53 24
					39 01 00 00 00 00 03 F0 A5 A5
					05 01 00 00 00 00 02 29 00
				];

				qcom,mdss-dsi-aod-ER2-low-command = [
					// 25 for Low Mode
					39 01 00 00 00 00 03 F0 5A 5A
					15 01 00 00 00 00 02 91 01
					15 01 00 00 10 00 02 53 25
					39 01 00 00 00 00 03 F0 A5 A5
					05 01 00 00 00 00 02 29 00
				];
				qcom,mdss-dsi-aod-other-command = [
					05 01 00 00 00 00 02 29 00
				];

				qcom,mdss-dsi-dimming-speed-1frame-command = [
					15 01 00 00 00 00 02 53 20
				];

				qcom,mdss-dsi-dimming-speed-20frame-command = [
					15 01 00 00 00 00 02 53 28
				];

				qcom,mdss-dsi-dimming-smooth-command = [
					15 01 00 00 00 00 02 53 28
				];


				qcom,mdss-dsi-aod-off-command = [
					05 01 00 00 10 00 02 28 00
				];

				qcom,mdss-dsi-on-command-state = "dsi_lp_mode";
				qcom,mdss-dsi-ER1-on-command-state = "dsi_lp_mode";
				qcom,mdss-dsi-off-command-state = "dsi_hs_mode";
				qcom,mdss-dsi-timing-switch-command-state = "dsi_hs_mode";
				qcom,mdss-dsi-hbm-on-command-state = "dsi_hs_mode";
				qcom,mdss-dsi-hbm-ER2-on-command-state = "dsi_hs_mode";
				qcom,mdss-dsi-ER1-cam-hbm-on-command-state = "dsi_hs_mode";
				qcom,mdss-dsi-ER2-cam-hbm-on-command-state = "dsi_hs_mode";
				qcom,mdss-dsi-hbm-off-command-state = "dsi_hs_mode";
				qcom,mdss-dsi-fod-hbm-on-command-state = "dsi_hs_mode";
				qcom,mdss-dsi-fod-ER2-hbm-on-command-state = "dsi_hs_mode";
				qcom,mdss-dsi-fod-hbm-off-command-state = "dsi_hs_mode";
				qcom,mdss-dsi-lp1-command-state = "dsi_hs_mode";
				qcom,mdss-dsi-nolp-command-state = "dsi_hs_mode";
				qcom,mdss-dsi-nolp-ER2-command-state = "dsi_hs_mode";
				qcom,mdss-dsi-nolp-ER2-FOD-command-state = "dsi_hs_mode";
				qcom,mdss-dsi-aod-high-command-state = "dsi_hs_mode";
				qcom,mdss-dsi-aod-low-command-state = "dsi_hs_mode";
				qcom,mdss-dsi-aod-ER2-high-command-state = "dsi_hs_mode";
				qcom,mdss-dsi-aod-ER2-low-command-state = "dsi_hs_mode";
				qcom,mdss-dsi-aod-other-command-state = "dsi_hs_mode";
				qcom,mdss-dsi-dimming-speed-1frame-command-state = "dsi_hs_mode";
				qcom,mdss-dsi-dimming-speed-20frame-command-state = "dsi_hs_mode";
				qcom,mdss-dsi-dimming-smooth-command-state = "dsi_hs_mode";
				qcom,mdss-dsi-aod-off-command-state = "dsi_hs_mode";

				/* DSC */
				qcom,compression-mode = "dsc";
				qcom,mdss-dsc-slice-height = <40>;
				qcom,mdss-dsc-slice-width = <540>;
				qcom,mdss-dsc-slice-per-pkt = <1>;
				qcom,mdss-dsc-bit-per-component = <8>;
				qcom,mdss-dsc-bit-per-pixel = <8>;
				qcom,mdss-dsc-block-prediction-enable;
			};
		};	
	};
};
